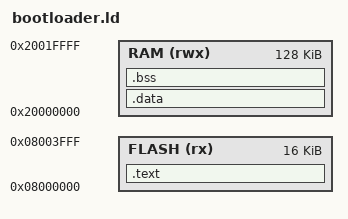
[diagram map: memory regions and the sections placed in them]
MEMORY
{
    FLASH (rx) : ORIGIN = 0x08000000, LENGTH = 16K
    RAM (rwx) : ORIGIN = 0x20000000, LENGTH = 128K
}

SECTIONS
{
    .text :
    {
        _start_text = .;
        KEEP(*(.isr_vector))
        . = 0x400;
        KEEP(*(.utils))
        *(.text*)
        *(.rodata*)
        . = ALIGN(4);
        _end_text = .;
    } > FLASH

    _stored_data = .;
    .data : AT (_stored_data)
    {
        _start_data = .;
        *(.data*)
        . = ALIGN(4);
        _end_data = .;
    } > RAM

    .bss :
    {
        _start_bss = .;
        *(.bss*)
        . = ALIGN(4);
        _end_bss = .;
        _end = .;
    } > RAM
}

END_STACK = ORIGIN(RAM) + LENGTH(RAM);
